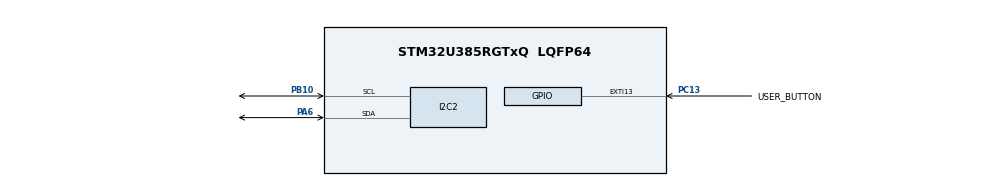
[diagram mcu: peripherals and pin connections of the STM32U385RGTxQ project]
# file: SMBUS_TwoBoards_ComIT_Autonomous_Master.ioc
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CORTEX_M33_NS.userName=CORTEX_M33
GPDMA1.DESTINC_GPDMACH0=DMA_DINC_INCREMENTED
GPDMA1.PRIORITY_GPDMACH0=DMA_HIGH_PRIORITY
GPDMA1.SRCINC_GPDMACH0=DMA_SINC_INCREMENTED
GPDMA1.TRANSFERALLOCATEDPORTDEST_GPDMACH0=DMA_DEST_ALLOCATED_PORT1
I2C2.AutonomousMode=AUTONOMOUS_MODE_ENABLE
I2C2.SMBusDualAddressMode=SMBUS_DUALADDRESS_ENABLE
I2C2.SMBusOwnAddress=0x42
I2C2.SMBusOwnAddress2=0xFF
I2C2.SMBusPeripheralMode=SMBUS_PERIPHERAL_MODE_SMBUS_HOST
I2C2.Timeout=0x00008493
I2C2.Timing=0x10B0DCFB
Mcu.Family=STM32U3
Mcu.Name=STM32U385RGTxQ
Mcu.Package=LQFP64
NVIC.EXTI13_IRQn=true\:0\:0\:false\:false\:true\:true\:true\:true
NVIC.GPDMA1_Channel0_IRQn=true\:0\:0\:false\:false\:true\:true\:true\:true
NVIC.I2C2_ER_IRQn=true\:0\:0\:false\:false\:true\:true\:true\:true
NVIC.I2C2_EV_IRQn=true\:0\:0\:false\:false\:true\:true\:true\:true
NVIC.PriorityGroup=NVIC_PRIORITYGROUP_4
PA6.GPIO_Pu=GPIO_PULLUP
PA6.Mode=SMBus-two-wire-Interface
PA6.Signal=I2C2_SDA
PB10.GPIO_Pu=GPIO_PULLUP
PB10.Mode=SMBus-two-wire-Interface
PB10.Signal=I2C2_SCL
PC13.GPIO_Label=USER_BUTTON
PC13.GPIO_ModeDefaultEXTI=GPIO_MODE_IT_RISING
PC13.GPIO_PuPd=GPIO_PULLDOWN
PC13.Signal=GPXTI13
ProjectManager.HeapSize=0x200
ProjectManager.StackSize=0x400
ProjectManager.TargetToolchain=EWARM V9.20
RCC.ADCFreq_Value=96000000
RCC.AHBFreq_Value=96000000
RCC.APB1Freq_Value=96000000
RCC.APB1TimFreq_Value=96000000
RCC.APB2Freq_Value=96000000
RCC.APB2TimFreq_Value=96000000
RCC.APB3Freq_Value=96000000
RCC.CortexFreq_Value=12000000
RCC.HCLKFreq_Value=96000000
RCC.HSE_VALUE=16000000
RCC.HSI48_VALUE=48000000
RCC.HSI_VALUE=16000000
RCC.LSE_VALUE=32768
RCC.LSIDIV_VALUE=32000
RCC.MSISDIV=RCC_MSI_DIV1
RCC.SYSCLKFreq_VALUE=96000000
RCC.USBFreq_Value=96000000
VP_GPDMA1_VS_GPDMACH0.Mode=SIMPLEREQUEST_GPDMACH0
VP_ICACHE_VS_ICACHE.Mode=DirectMappedCache
VP_PWR_VS_DBSignals.Mode=DisableDeadBatterySignals
VP_PWR_VS_LPOM.Mode=PowerOptimisation
VP_PWR_VS_SECSignals.Mode=Security/Privilege
board=custom

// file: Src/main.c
/* USER CODE BEGIN Header */
/**
  ******************************************************************************
  * @file    SMBUS/SMBUS_TwoBoards_ComIT_Autonomous_Master/Src/main.c
  * @author  MCD Application Team
  * @brief   This sample code shows how to use SMBUS HAL API (SMBUS instance)
  *          to set up a SMBUS-SPI communication.
  *          Two boards are used, one configured as a SPI master and the second
  *          one configured as an SMBUS slave.
  ******************************************************************************
  * @attention
  *
  * Copyright (c) 2024 STMicroelectronics.
  * All rights reserved.
  *
  * This software is licensed under terms that can be found in the LICENSE file
  * in the root directory of this software component.
  * If no LICENSE file comes with this software, it is provided AS-IS.
  *
  ******************************************************************************
  */
/* USER CODE END Header */
#include "main.h"

/* USER CODE BEGIN PD */
#define SMBUS_ADDRESS          0x42

/* Address match */
__IO uint32_t SlaveAddrMatchCode = 0;

/* Buffer used for SMBUS transmission */
uint8_t aTxBuffer[] = " ****SMBUS_TwoBoards communication using autonomous mode functionality ****  ****SMBUS_TwoBoards communication using autonomous mode functionality **** ";

/* Buffer used for SMBUS reception */
uint8_t aRxBuffer[RXBUFFERSIZE];

/* Buffer used for DMA transmission */
uint8_t aTxConstBuffer[] = " ****SMBUS communication based on IT****  ****SMBUS communication based on IT****  ****SMBUS communication based on IT**** ";

/* Buffer used for DMA reception */
uint8_t aRxConstBuffer[RXCONSTBUFFERSIZE];

/* USER CODE END PD */

DMA_HandleTypeDef handle_GPDMA1_Channel0;

SMBUS_HandleTypeDef hsmbus2;

void SystemClock_Config(void);
static void MX_GPIO_Init(void);
static void MX_GPDMA1_Init(void);
static void MX_ICACHE_Init(void);
static void MX_I2C2_SMBUS_Init(void);

int main(void)
{

  /* USER CODE BEGIN 1 */
  /* STM32U3xx HAL library initialization:
       - Configure the Flash prefetch
       - Configure the Systick to generate an interrupt each 1 msec
       - Set NVIC Group Priority to 3
       - Low Level Initialization
     */
  /* USER CODE END 1 */

  /* MCU Configuration--------------------------------------------------------*/

  /* Reset of all peripherals, Initializes the Flash interface and the Systick. */
  HAL_Init();

  /* Configure the system clock */
  SystemClock_Config();

  /* USER CODE BEGIN SysInit */
  /* Configure LD2 */
  BSP_LED_Init(LD2);
  /* USER CODE END SysInit */

  /* Initialize all configured peripherals */
  MX_GPIO_Init();
  MX_GPDMA1_Init();
  MX_ICACHE_Init();
  MX_I2C2_SMBUS_Init();
  /* USER CODE BEGIN 2 */
  /* Enable the Analog SMBUS Filter */
  HAL_SMBUS_ConfigAnalogFilter(&hsmbus2,SMBUS_ANALOGFILTER_ENABLE);

  /* Configure User push-button */
  BSP_PB_Init(BUTTON_USER,BUTTON_MODE_GPIO);

  /* Wait for User push-button press before starting the Communication */
  while (BSP_PB_GetState(BUTTON_USER) != GPIO_PIN_SET)
  {
    BSP_LED_Toggle(LD2);
    HAL_Delay(100);
  }
  BSP_LED_Off(LD2);

  /* Delay to avoid that possible signal rebound is taken as button release */
  HAL_Delay(50);

  /* Wait for User push-button release before starting the Communication */
  while (BSP_PB_GetState(BUTTON_USER) != GPIO_PIN_RESET)
  {
  }

  /*##-2- Start the transmission process #####################################*/
  /* While the SMBUS in reception process, user can transmit data through
     "aTxBuffer" buffer */
  HAL_SMBUS_Master_Transmit_IT(&hsmbus2, (uint16_t)SMBUS_ADDRESS, (uint8_t*)aTxBuffer, TXBUFFERSIZE, SMBUS_FIRST_AND_LAST_FRAME_NO_PEC);

  /* Start the DMA transfer */
  HAL_DMA_Start_IT(&handle_GPDMA1_Channel0, (uint32_t) &aTxConstBuffer, (uint32_t) &aRxConstBuffer, TXCONSTBUFFERSIZE);

  /*wait end of SMBUS tranfert*/
  while (hsmbus2.State != HAL_SMBUS_STATE_READY);
  BSP_LED_On(LD2);

  /* USER CODE END 2 */

  /* Infinite loop */
  while (1)
  {

  }
}

void SystemClock_Config(void)
{
  RCC_OscInitTypeDef RCC_OscInitStruct = {0};
  RCC_ClkInitTypeDef RCC_ClkInitStruct = {0};

    /** Enable Epod Booster
    */
  if (HAL_RCCEx_EpodBoosterClkConfig(RCC_EPODBOOSTER_SOURCE_MSIS, RCC_EPODBOOSTER_DIV1) != HAL_OK)
  {
    Error_Handler();
  }
  if (HAL_PWREx_EnableEpodBooster() != HAL_OK)
  {
    Error_Handler();
  }

    /** Configure the main internal regulator output voltage
    */
  if (HAL_PWREx_ControlVoltageScaling(PWR_REGULATOR_VOLTAGE_SCALE1) != HAL_OK)
  {
    Error_Handler();
  }

    /** Set Flash latency before increasing MSIS
    */
  __HAL_FLASH_SET_LATENCY(FLASH_LATENCY_2);

    /** Initializes the CPU, AHB and APB buses clocks
    */
  RCC_OscInitStruct.OscillatorType = RCC_OSCILLATORTYPE_MSIS;
  RCC_OscInitStruct.MSISState = RCC_MSI_ON;
  RCC_OscInitStruct.MSISSource = RCC_MSI_RC0;
  RCC_OscInitStruct.MSISDiv = RCC_MSI_DIV1;
  if (HAL_RCC_OscConfig(&RCC_OscInitStruct) != HAL_OK)
  {
    Error_Handler();
  }

    /** Initializes the CPU, AHB and APB buses clocks
    */
  RCC_ClkInitStruct.ClockType = RCC_CLOCKTYPE_HCLK|RCC_CLOCKTYPE_SYSCLK
                              |RCC_CLOCKTYPE_PCLK1|RCC_CLOCKTYPE_PCLK2
                              |RCC_CLOCKTYPE_PCLK3;
  RCC_ClkInitStruct.SYSCLKSource = RCC_SYSCLKSOURCE_MSIS;
  RCC_ClkInitStruct.AHBCLKDivider = RCC_SYSCLK_DIV1;
  RCC_ClkInitStruct.APB1CLKDivider = RCC_HCLK_DIV1;
  RCC_ClkInitStruct.APB2CLKDivider = RCC_HCLK_DIV1;
  RCC_ClkInitStruct.APB3CLKDivider = RCC_HCLK_DIV1;

  if (HAL_RCC_ClockConfig(&RCC_ClkInitStruct, FLASH_LATENCY_2) != HAL_OK)
  {
    Error_Handler();
  }
}

static void MX_GPDMA1_Init(void)
{

  /* Peripheral clock enable */
  __HAL_RCC_GPDMA1_CLK_ENABLE();

  /* GPDMA1 interrupt Init */
    HAL_NVIC_SetPriority(GPDMA1_Channel0_IRQn, 0, 0);
    HAL_NVIC_EnableIRQ(GPDMA1_Channel0_IRQn);

  handle_GPDMA1_Channel0.Instance = GPDMA1_Channel0;
  handle_GPDMA1_Channel0.Init.Request = DMA_REQUEST_SW;
  handle_GPDMA1_Channel0.Init.BlkHWRequest = DMA_BREQ_SINGLE_BURST;
  handle_GPDMA1_Channel0.Init.Direction = DMA_MEMORY_TO_MEMORY;
  handle_GPDMA1_Channel0.Init.SrcInc = DMA_SINC_INCREMENTED;
  handle_GPDMA1_Channel0.Init.DestInc = DMA_DINC_INCREMENTED;
  handle_GPDMA1_Channel0.Init.SrcDataWidth = DMA_SRC_DATAWIDTH_BYTE;
  handle_GPDMA1_Channel0.Init.DestDataWidth = DMA_DEST_DATAWIDTH_BYTE;
  handle_GPDMA1_Channel0.Init.Priority = DMA_HIGH_PRIORITY;
  handle_GPDMA1_Channel0.Init.SrcBurstLength = 1;
  handle_GPDMA1_Channel0.Init.DestBurstLength = 1;
  handle_GPDMA1_Channel0.Init.TransferAllocatedPort = DMA_SRC_ALLOCATED_PORT0|DMA_DEST_ALLOCATED_PORT1;
  handle_GPDMA1_Channel0.Init.TransferEventMode = DMA_TCEM_BLOCK_TRANSFER;
  handle_GPDMA1_Channel0.Init.Mode = DMA_NORMAL;
  if (HAL_DMA_Init(&handle_GPDMA1_Channel0) != HAL_OK)
  {
    Error_Handler();
  }
  if (HAL_DMA_ConfigChannelAttributes(&handle_GPDMA1_Channel0, DMA_CHANNEL_NPRIV) != HAL_OK)
  {
    Error_Handler();
  }

}

static void MX_I2C2_SMBUS_Init(void)
{

  SMBUS_AutonomousModeConfTypeDef sConfigI2C2 = {0};

  hsmbus2.Instance = I2C2;
  hsmbus2.Init.Timing = 0x10B0DCFB;
  hsmbus2.Init.AnalogFilter = SMBUS_ANALOGFILTER_ENABLE;
  hsmbus2.Init.OwnAddress1 = 0x42;
  hsmbus2.Init.AddressingMode = SMBUS_ADDRESSINGMODE_7BIT;
  hsmbus2.Init.DualAddressMode = SMBUS_DUALADDRESS_ENABLE;
  hsmbus2.Init.OwnAddress2 = 0xFF;
  hsmbus2.Init.OwnAddress2Masks = SMBUS_OA2_NOMASK;
  hsmbus2.Init.GeneralCallMode = SMBUS_GENERALCALL_DISABLE;
  hsmbus2.Init.NoStretchMode = SMBUS_NOSTRETCH_DISABLE;
  hsmbus2.Init.PacketErrorCheckMode = SMBUS_PEC_DISABLE;
  hsmbus2.Init.PeripheralMode = SMBUS_PERIPHERAL_MODE_SMBUS_HOST;
  hsmbus2.Init.SMBusTimeout = 0x00008493;
  if (HAL_SMBUS_Init(&hsmbus2) != HAL_OK)
  {
    Error_Handler();
  }

    /** Configure Autonomous Mode
    */
  sConfigI2C2.TriggerState = SMBUS_AUTO_MODE_ENABLE;
  sConfigI2C2.TriggerSelection = SMBUS_GRP1_GPDMA_CH0_TCF_TRG;
  sConfigI2C2.TriggerPolarity = SMBUS_TRIG_POLARITY_RISING;
  if (HAL_SMBUSEx_SetConfigAutonomousMode(&hsmbus2, &sConfigI2C2) != HAL_OK)
  {
    Error_Handler();
  }

}

static void MX_ICACHE_Init(void)
{

    /** Enable instruction cache in 1-way (direct mapped cache)
    */
  if (HAL_ICACHE_ConfigAssociativityMode(ICACHE_1WAY) != HAL_OK)
  {
    Error_Handler();
  }
  if (HAL_ICACHE_Enable() != HAL_OK)
  {
    Error_Handler();
  }

}

static void MX_GPIO_Init(void)
{
  GPIO_InitTypeDef GPIO_InitStruct = {0};

  /* GPIO Ports Clock Enable */
  __HAL_RCC_GPIOC_CLK_ENABLE();
  __HAL_RCC_GPIOA_CLK_ENABLE();
  __HAL_RCC_GPIOB_CLK_ENABLE();

  /*Configure GPIO pin : USER_BUTTON_Pin */
  GPIO_InitStruct.Pin = USER_BUTTON_Pin;
  GPIO_InitStruct.Mode = GPIO_MODE_IT_RISING;
  GPIO_InitStruct.Pull = GPIO_PULLDOWN;
  HAL_GPIO_Init(USER_BUTTON_GPIO_Port, &GPIO_InitStruct);

  /* EXTI interrupt init*/
  HAL_NVIC_SetPriority(EXTI13_IRQn, 0, 0);
  HAL_NVIC_EnableIRQ(EXTI13_IRQn);

}

/* USER CODE BEGIN 4 */
/**
  * @brief  SMBUS error callbacks.
  * @param  SMBUSHandle: SMBUS handle
  * @note   This example shows a simple way to report transfer error, and you can
  *         add your own implementation.
  * @retval None
  */
void HAL_SMBUS_ErrorCallback(SMBUS_HandleTypeDef *SMBUSHandle)
{
  /** Error_Handler() function is called when error occurs.
    * 1- When Slave doesn't acknowledge its address, Master restarts communication.
    * 2- When Master doesn't acknowledge the last data transferred, Slave doesn't care in this example.
    */
  if (HAL_SMBUS_GetError(SMBUSHandle) != HAL_SMBUS_ERROR_ACKF)
  {
    /* Turn Off LD2 */
    BSP_LED_Off(LD2);
  }
}

/**
  * @brief EXTI line detection callbacks
  * @param GPIO_Pin: Specifies the pins connected EXTI line
  * @retval None
  */
void HAL_GPIO_EXTI_Rising_Callback(uint16_t GPIO_Pin)
{
  if (GPIO_Pin == BUTTON_USER_PIN)
  {
    /* Turn Off LD2 */
    BSP_LED_Off(LD2);

  }
}

/* USER CODE END 4 */

void Error_Handler(void)
{
  /* USER CODE BEGIN Error_Handler_Debug */
  /* Turn LD2 off */
  BSP_LED_Off(LD2);
  while(1)
  {
  }
  __disable_irq();
  while (1)
  {
  }
  /* USER CODE END Error_Handler_Debug */
}
